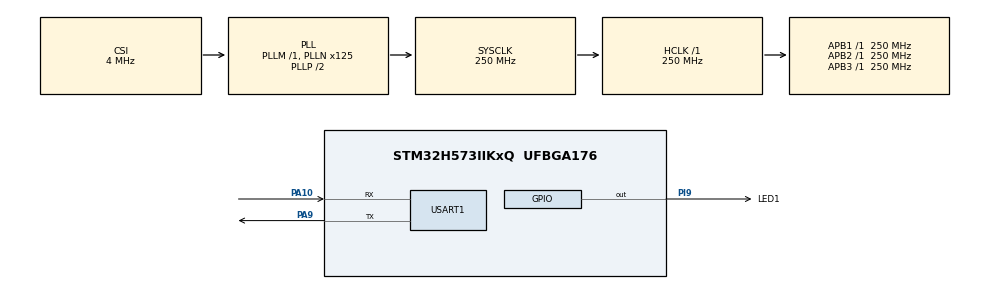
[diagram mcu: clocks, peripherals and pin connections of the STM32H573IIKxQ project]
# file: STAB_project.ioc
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BOOTPATH.BootPathName=LEGACY
BOOTPATH.UserSelectedBootPath=LEGACY
CORTEX_M33_NS.userName=CORTEX_M33
Mcu.Family=STM32H5
Mcu.Name=STM32H573IIKxQ
Mcu.Package=UFBGA176
NVIC.PriorityGroup=NVIC_PRIORITYGROUP_4
PA10.Mode=Asynchronous
PA10.Signal=USART1_RX
PA9.Mode=Asynchronous
PA9.Signal=USART1_TX
PH0-OSC_IN(PH0).Mode=HSE-DIG-External-Clock-Source
PH0-OSC_IN(PH0).Signal=RCC_OSC_IN
PI9.GPIO_Label=LED1
PI9.Signal=GPIO_Output
ProjectManager.HeapSize=0x200
ProjectManager.StackSize=0x400
ProjectManager.TargetToolchain=STM32CubeIDE
RCC.ADCFreq_Value=250000000
RCC.AHBFreq_Value=250000000
RCC.APB1Freq_Value=250000000
RCC.APB1TimFreq_Value=250000000
RCC.APB2Freq_Value=250000000
RCC.APB2TimFreq_Value=250000000
RCC.APB3Freq_Value=250000000
RCC.CSI_VALUE=4000000
RCC.CortexFreq_Value=250000000
RCC.EPOD_VALUE=4000000
RCC.HCLKFreq_Value=250000000
RCC.HSE_VALUE=25000000
RCC.HSI48_VALUE=48000000
RCC.HSI_VALUE=64000000
RCC.LSE_VALUE=32768
RCC.LSIRC_VALUE=32000
RCC.PLLFRACN=0
RCC.PLLN=125
RCC.SYSCLKFreq_VALUE=250000000
RCC.SYSCLKSource=RCC_SYSCLKSOURCE_PLLCLK
RCC.USBFreq_Value=48000000
RCC.VCOOutputFreq_Value=500000000
USART1.VirtualMode-Asynchronous=VM_ASYNC
VP_BOOTPATH_VS_BOOTPATH.Mode=BP_Activate
VP_CORTEX_M33_NS_VS_Hclk.Mode=Hclk_Mode
VP_ICACHE_VS_ICACHE.Mode=DefaultMode
VP_MEMORYMAP_VS_MEMORYMAP.Mode=CurAppReg
VP_PWR_VS_LPOM.Mode=PowerOptimisation
VP_PWR_VS_SECSignals.Mode=Security/Privilege
board=custom

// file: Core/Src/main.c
/* USER CODE BEGIN Header */
/**
  ******************************************************************************
  * @file           : main.c
  * @brief          : Main program body
  ******************************************************************************
  * @attention
  *
  * Copyright (c) 2025 STMicroelectronics.
  * All rights reserved.
  *
  * This software is licensed under terms that can be found in the LICENSE file
  * in the root directory of this software component.
  * If no LICENSE file comes with this software, it is provided AS-IS.
  *
  ******************************************************************************
  */
/* USER CODE END Header */
#include "main.h"

/* USER CODE BEGIN Includes */
#include "icache.h"
#include "gpio.h"
#include "lfs.h"
#include "lfs_util.h"
#include "lfs_config.h"
#include "usart.h"

/* USER CODE END Includes */

/* USER CODE BEGIN PD */
#define USER_LED2_Pin GPIO_PIN_8
#define USER_LED2_GPIO_Port GPIOI
/* USER CODE END PD */

void SystemClock_Config(void);

int main(void)
{

  /* MCU Configuration--------------------------------------------------------*/

  /* Reset of all peripherals, Initializes the Flash interface and the Systick. */
  HAL_Init();

  /* Configure the system clock */
  SystemClock_Config();

  /* Initialize all configured peripherals */
  MX_GPIO_Init();
  MX_ICACHE_Init();
  MX_USART1_UART_Init();
  /* USER CODE BEGIN 2 */
  extern struct lfs_config cfg;
  lfs_t lfs;
  int err = lfs_mount(&lfs, &cfg);

  // Test UART : Remplacement de printf() par HAL_UART_Transmit
  uint8_t msg_start[] = "Demarrage du système...\r\n";
  HAL_UART_Transmit(&huart1, msg_start, sizeof(msg_start) - 1, HAL_MAX_DELAY);

  if (err) {
      uint8_t msg_format[] = "LittleFS non monte, formatage...\r\n";
      HAL_UART_Transmit(&huart1, msg_format, sizeof(msg_format) - 1, HAL_MAX_DELAY);

      lfs_format(&lfs, &cfg);
      err = lfs_mount(&lfs, &cfg);
  }

  if (err == 0) {
      lfs_file_t file;
      const char *text = "Bonjour SRAM3 !";
      char buffer[128];

      // Écriture du fichier
      uint8_t msg_write[] = "Ecriture dans monfichier.txt...\r\n";
      HAL_UART_Transmit(&huart1, msg_write, sizeof(msg_write) - 1, HAL_MAX_DELAY);

      if (lfs_file_open(&lfs, &file, "monfichier.txt", LFS_O_WRONLY | LFS_O_CREAT) == 0) {
          lfs_file_write(&lfs, &file, text, strlen(text));
          lfs_file_close(&lfs, &file);

          uint8_t msg_success[] = "Ecriture reussie\r\n";
          HAL_UART_Transmit(&huart1, msg_success, sizeof(msg_success) - 1, HAL_MAX_DELAY);
      } else {
          uint8_t msg_error_open[] = "Erreur : ouverture du fichier en ecriture\r\n";
          HAL_UART_Transmit(&huart1, msg_error_open, sizeof(msg_error_open) - 1, HAL_MAX_DELAY);
      }

      // Lecture du fichier
      uint8_t msg_read[] = "Lecture de monfichier.txt...\r\n";
      HAL_UART_Transmit(&huart1, msg_read, sizeof(msg_read) - 1, HAL_MAX_DELAY);

      if (lfs_file_open(&lfs, &file, "monfichier.txt", LFS_O_RDONLY) == 0) {
          lfs_ssize_t bytes_read = lfs_file_read(&lfs, &file, buffer, sizeof(buffer) - 1);
          if (bytes_read > 0) {
              buffer[bytes_read] = '\0'; // Terminaison de chaîne
              uint8_t msg_content[] = "Contenu lu : ";
              HAL_UART_Transmit(&huart1, msg_content, sizeof(msg_content) - 1, HAL_MAX_DELAY);
              HAL_UART_Transmit(&huart1, (uint8_t*)buffer, strlen(buffer), HAL_MAX_DELAY);
              uint8_t msg_newline[] = "\r\n";
              HAL_UART_Transmit(&huart1, msg_newline, sizeof(msg_newline) - 1, HAL_MAX_DELAY);
          } else {
              uint8_t msg_read_error[] = "Erreur : lecture du fichier\r\n";
              HAL_UART_Transmit(&huart1, msg_read_error, sizeof(msg_read_error) - 1, HAL_MAX_DELAY);
          }
          lfs_file_close(&lfs, &file);
      } else {
          uint8_t msg_read_open_error[] = "Erreur : ouverture du fichier en lecture\r\n";
          HAL_UART_Transmit(&huart1, msg_read_open_error, sizeof(msg_read_open_error) - 1, HAL_MAX_DELAY);
      }

      // Boucle LED + message
      uint8_t msg_loop[] = "Demarrage de la boucle LED...\r\n";
      HAL_UART_Transmit(&huart1, msg_loop, sizeof(msg_loop) - 1, HAL_MAX_DELAY);

      while (1) {
          HAL_GPIO_WritePin(LED1_GPIO_Port, LED1_Pin, GPIO_PIN_SET);

          uint8_t msg_on[] = "LED ON\r\n";
          HAL_UART_Transmit(&huart1, msg_on, sizeof(msg_on) - 1, HAL_MAX_DELAY);

          HAL_Delay(1000);

          HAL_GPIO_WritePin(LED1_GPIO_Port, LED1_Pin, GPIO_PIN_RESET);

          uint8_t msg_off[] = "LED OFF\r\n";
          HAL_UART_Transmit(&huart1, msg_off, sizeof(msg_off) - 1, HAL_MAX_DELAY);

          HAL_Delay(1000);
      }
  } else {
      uint8_t msg_fatal_error[] = "Erreur fatale : impossible de monter LittleFS\r\n";
      HAL_UART_Transmit(&huart1, msg_fatal_error, sizeof(msg_fatal_error) - 1, HAL_MAX_DELAY);

      HAL_GPIO_WritePin(LED1_GPIO_Port, LED1_Pin, GPIO_PIN_RESET);
      while (1); // Boucle infinie en cas d'erreur
  }
  /* USER CODE END 2 */

   /* Infinite loop */
   while (1)
   {
   }
   /* USER CODE END 3 */
 }
void SystemClock_Config(void)
{
  RCC_OscInitTypeDef RCC_OscInitStruct = {0};
  RCC_ClkInitTypeDef RCC_ClkInitStruct = {0};

  /** Configure the main internal regulator output voltage
  */
  __HAL_PWR_VOLTAGESCALING_CONFIG(PWR_REGULATOR_VOLTAGE_SCALE0);

  while(!__HAL_PWR_GET_FLAG(PWR_FLAG_VOSRDY)) {}

  /** Initializes the RCC Oscillators according to the specified parameters
  * in the RCC_OscInitTypeDef structure.
  */
  RCC_OscInitStruct.OscillatorType = RCC_OSCILLATORTYPE_CSI;
  RCC_OscInitStruct.CSIState = RCC_CSI_ON;
  RCC_OscInitStruct.CSICalibrationValue = RCC_CSICALIBRATION_DEFAULT;
  RCC_OscInitStruct.PLL.PLLState = RCC_PLL_ON;
  RCC_OscInitStruct.PLL.PLLSource = RCC_PLL1_SOURCE_CSI;
  RCC_OscInitStruct.PLL.PLLM = 1;
  RCC_OscInitStruct.PLL.PLLN = 125;
  RCC_OscInitStruct.PLL.PLLP = 2;
  RCC_OscInitStruct.PLL.PLLQ = 2;
  RCC_OscInitStruct.PLL.PLLR = 2;
  RCC_OscInitStruct.PLL.PLLRGE = RCC_PLL1_VCIRANGE_2;
  RCC_OscInitStruct.PLL.PLLVCOSEL = RCC_PLL1_VCORANGE_WIDE;
  RCC_OscInitStruct.PLL.PLLFRACN = 0;
  if (HAL_RCC_OscConfig(&RCC_OscInitStruct) != HAL_OK)
  {
    Error_Handler();
  }

  /** Initializes the CPU, AHB and APB buses clocks
  */
  RCC_ClkInitStruct.ClockType = RCC_CLOCKTYPE_HCLK|RCC_CLOCKTYPE_SYSCLK
                              |RCC_CLOCKTYPE_PCLK1|RCC_CLOCKTYPE_PCLK2
                              |RCC_CLOCKTYPE_PCLK3;
  RCC_ClkInitStruct.SYSCLKSource = RCC_SYSCLKSOURCE_PLLCLK;
  RCC_ClkInitStruct.AHBCLKDivider = RCC_SYSCLK_DIV1;
  RCC_ClkInitStruct.APB1CLKDivider = RCC_HCLK_DIV1;
  RCC_ClkInitStruct.APB2CLKDivider = RCC_HCLK_DIV1;
  RCC_ClkInitStruct.APB3CLKDivider = RCC_HCLK_DIV1;

  if (HAL_RCC_ClockConfig(&RCC_ClkInitStruct, FLASH_LATENCY_5) != HAL_OK)
  {
    Error_Handler();
  }

  /** Configure the programming delay
  */
  __HAL_FLASH_SET_PROGRAM_DELAY(FLASH_PROGRAMMING_DELAY_2);
}

void MX_ICACHE_Init(void)
{

  /** Enable instruction cache (default 2-ways set associative cache)
  */
  if (HAL_ICACHE_Enable() != HAL_OK)
  {
    Error_Handler();
  }
}

void MX_GPIO_Init(void)
{
  GPIO_InitTypeDef GPIO_InitStruct = {0};

  /* GPIO Ports Clock Enable */
  __HAL_RCC_GPIOI_CLK_ENABLE();
  __HAL_RCC_GPIOH_CLK_ENABLE();

  /*Configure GPIO pin Output Level */
  HAL_GPIO_WritePin(LED1_GPIO_Port, LED1_Pin, GPIO_PIN_RESET);

  /*Configure GPIO pin : LED1_Pin */
  GPIO_InitStruct.Pin = LED1_Pin;
  GPIO_InitStruct.Mode = GPIO_MODE_OUTPUT_PP;
  GPIO_InitStruct.Pull = GPIO_NOPULL;
  GPIO_InitStruct.Speed = GPIO_SPEED_FREQ_LOW;
  HAL_GPIO_Init(LED1_GPIO_Port, &GPIO_InitStruct);

}

void Error_Handler(void)
{
  __disable_irq();
  while (1)
  {
  }
}
